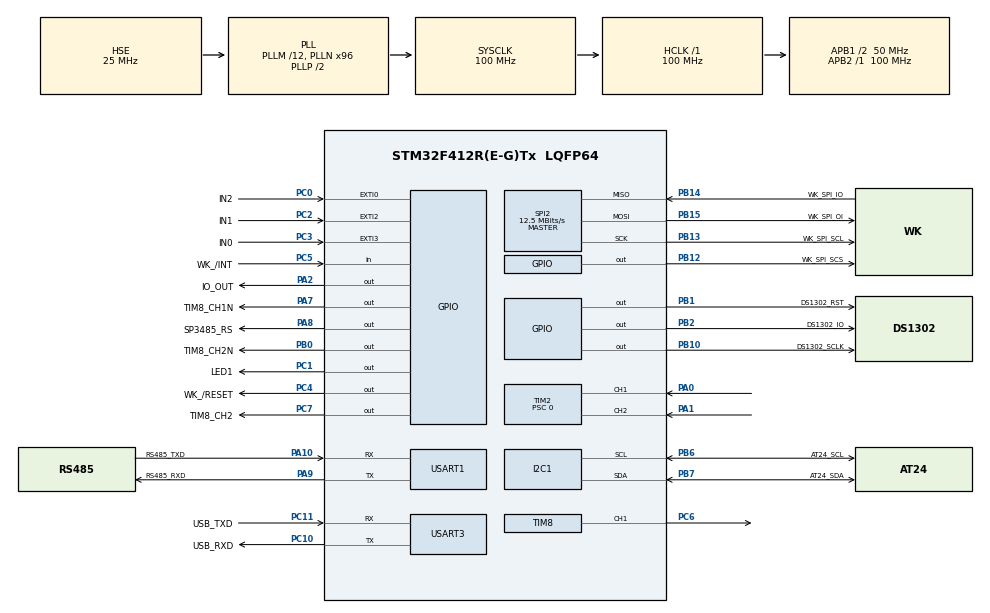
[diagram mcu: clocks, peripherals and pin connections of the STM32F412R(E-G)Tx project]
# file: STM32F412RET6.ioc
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Dma.Request0=USART1_RX
Dma.Request1=USART1_TX
Dma.USART1_RX.0.Direction=DMA_PERIPH_TO_MEMORY
Dma.USART1_RX.0.FIFOMode=DMA_FIFOMODE_DISABLE
Dma.USART1_RX.0.Instance=DMA2_Stream2
Dma.USART1_RX.0.MemDataAlignment=DMA_MDATAALIGN_BYTE
Dma.USART1_RX.0.MemInc=DMA_MINC_ENABLE
Dma.USART1_RX.0.Mode=DMA_NORMAL
Dma.USART1_RX.0.PeriphDataAlignment=DMA_PDATAALIGN_BYTE
Dma.USART1_RX.0.PeriphInc=DMA_PINC_DISABLE
Dma.USART1_RX.0.Priority=DMA_PRIORITY_LOW
Dma.USART1_TX.1.Direction=DMA_MEMORY_TO_PERIPH
Dma.USART1_TX.1.FIFOMode=DMA_FIFOMODE_DISABLE
Dma.USART1_TX.1.Instance=DMA2_Stream7
Dma.USART1_TX.1.MemDataAlignment=DMA_MDATAALIGN_BYTE
Dma.USART1_TX.1.MemInc=DMA_MINC_ENABLE
Dma.USART1_TX.1.Mode=DMA_NORMAL
Dma.USART1_TX.1.PeriphDataAlignment=DMA_PDATAALIGN_BYTE
Dma.USART1_TX.1.PeriphInc=DMA_PINC_DISABLE
Dma.USART1_TX.1.Priority=DMA_PRIORITY_LOW
FREERTOS.Queues01=myQueue01,5,uint8_t,0,Dynamic,NULL,NULL
FREERTOS.Tasks01=defaultTask,24,128,StartDefaultTask,Default,NULL,Dynamic,NULL,NULL;myTask01,8,128,StartTask01,Default,NULL,Dynamic,NULL,NULL
FREERTOS.configMAX_TASK_NAME_LEN=32
I2C1.I2C_Mode=I2C_Fast
Mcu.Family=STM32F4
Mcu.Name=STM32F412R(E-G)Tx
Mcu.Package=LQFP64
NVIC.DMA2_Stream2_IRQn=true\:5\:0\:false\:false\:true\:true\:false\:true\:true
NVIC.DMA2_Stream7_IRQn=true\:5\:0\:false\:false\:true\:true\:false\:true\:true
NVIC.EXTI0_IRQn=true\:5\:0\:false\:false\:true\:true\:true\:true\:true
NVIC.EXTI2_IRQn=true\:5\:0\:false\:false\:true\:true\:true\:true\:true
NVIC.EXTI3_IRQn=true\:5\:0\:false\:false\:true\:true\:true\:true\:true
NVIC.I2C1_ER_IRQn=true\:5\:0\:false\:false\:true\:true\:true\:true\:true
NVIC.I2C1_EV_IRQn=true\:5\:0\:false\:false\:true\:true\:true\:true\:true
NVIC.PriorityGroup=NVIC_PRIORITYGROUP_4
NVIC.SPI2_IRQn=true\:5\:0\:false\:false\:true\:true\:true\:true\:true
NVIC.TIM1_UP_TIM10_IRQn=true\:15\:0\:false\:false\:true\:false\:false\:true\:true
NVIC.TIM2_IRQn=true\:5\:0\:true\:false\:true\:true\:true\:true\:true
NVIC.TIM3_IRQn=true\:6\:0\:true\:false\:true\:true\:true\:true\:true
NVIC.TIM8_BRK_TIM12_IRQn=true\:5\:0\:false\:false\:true\:true\:true\:true\:true
NVIC.TIM8_CC_IRQn=true\:5\:0\:false\:false\:true\:true\:true\:true\:true
NVIC.TIM8_TRG_COM_TIM14_IRQn=true\:5\:0\:false\:false\:true\:true\:true\:true\:true
NVIC.TIM8_UP_TIM13_IRQn=true\:5\:0\:false\:false\:true\:true\:true\:true\:true
NVIC.TimeBase=TIM1_UP_TIM10_IRQn
NVIC.TimeBaseIP=TIM1
NVIC.USART1_IRQn=true\:5\:0\:false\:false\:true\:true\:true\:true\:true
NVIC.USART3_IRQn=true\:5\:0\:false\:false\:true\:true\:true\:true\:true
PA0.GPIO_PuPd=GPIO_PULLUP
PA0.Signal=S_TIM2_CH1_ETR
PA1.GPIO_PuPd=GPIO_PULLUP
PA1.Signal=S_TIM2_CH2
PA10.GPIO_Label=RS485_TXD
PA10.Mode=Asynchronous
PA10.Signal=USART1_RX
PA13.GPIO_Label=TMS
PA13.Mode=JTAG_5_pins
PA13.Signal=SYS_JTMS-SWDIO
PA14.GPIO_Label=TCK
PA14.Mode=JTAG_5_pins
PA14.Signal=SYS_JTCK-SWCLK
PA15.GPIO_Label=TDI
PA15.Mode=JTAG_5_pins
PA15.Signal=SYS_JTDI
PA2.GPIO_Label=IO_OUT
PA2.GPIO_PuPd=GPIO_PULLDOWN
PA2.Signal=GPIO_Output
PA7.GPIO_Label=TIM8_CH1N
PA7.GPIO_PuPd=GPIO_PULLDOWN
PA7.Signal=GPIO_Output
PA8.GPIO_Label=SP3485_RS
PA8.Signal=GPIO_Output
PA9.GPIO_Label=RS485_RXD
PA9.Mode=Asynchronous
PA9.Signal=USART1_TX
PB0.GPIO_Label=TIM8_CH2N
PB0.GPIO_PuPd=GPIO_PULLUP
PB0.Signal=GPIO_Output
PB1.GPIO_Label=DS1302_RST
PB1.Signal=GPIO_Output
PB10.GPIO_Label=DS1302_SCLK
PB10.GPIO_PuPd=GPIO_PULLUP
PB10.Signal=GPIO_Output
PB12.GPIO_Label=WK_SPI_SCS
PB12.GPIO_ModeDefaultOutputPP=GPIO_MODE_OUTPUT_PP
PB12.GPIO_PuPd=GPIO_PULLUP
PB12.Signal=GPIO_Output
PB13.GPIO_Label=WK_SPI_SCL
PB13.Mode=Full_Duplex_Master
PB13.Signal=SPI2_SCK
PB14.GPIO_Label=WK_SPI_IO
PB14.Mode=Full_Duplex_Master
PB14.Signal=SPI2_MISO
PB15.GPIO_Label=WK_SPI_OI
PB15.Mode=Full_Duplex_Master
PB15.Signal=SPI2_MOSI
PB2.GPIO_Label=DS1302_IO
PB2.Signal=GPIO_Output
PB3.GPIO_Label=TDO
PB3.Mode=JTAG_5_pins
PB3.Signal=SYS_JTDO-SWO
PB4.GPIO_Label=NTRST
PB4.Mode=JTAG_5_pins
PB4.Signal=SYS_JTRST
PB6.GPIO_Label=AT24_SCL
PB6.Mode=I2C
PB6.Signal=I2C1_SCL
PB7.GPIO_Label=AT24_SDA
PB7.Mode=I2C
PB7.Signal=I2C1_SDA
PC0.GPIO_Label=IN2
PC0.GPIO_ModeDefaultEXTI=GPIO_MODE_IT_FALLING
PC0.Signal=GPXTI0
PC1.GPIO_Label=LED1
PC1.GPIO_PuPd=GPIO_PULLUP
PC1.Signal=GPIO_Output
PC10.GPIO_Label=USB_RXD
PC10.Mode=Asynchronous
PC10.Signal=USART3_TX
PC11.GPIO_Label=USB_TXD
PC11.Mode=Asynchronous
PC11.Signal=USART3_RX
PC2.GPIO_Label=IN1
PC2.GPIO_ModeDefaultEXTI=GPIO_MODE_IT_FALLING
PC2.Signal=GPXTI2
PC3.GPIO_Label=IN0
PC3.GPIO_ModeDefaultEXTI=GPIO_MODE_IT_FALLING
PC3.Signal=GPXTI3
PC4.GPIO_Label=WK_/RESET
PC4.Signal=GPIO_Output
PC5.GPIO_Label=WK_/INT
PC5.Signal=GPIO_Input
PC6.GPIO_Speed=GPIO_SPEED_FREQ_HIGH
PC6.Signal=S_TIM8_CH1
PC7.GPIO_Label=TIM8_CH2
PC7.GPIO_PuPd=GPIO_PULLUP
PC7.Signal=GPIO_Output
PH0\ -\ OSC_IN.Mode=HSE-External-Oscillator
PH0\ -\ OSC_IN.Signal=RCC_OSC_IN
PH1\ -\ OSC_OUT.Mode=HSE-External-Oscillator
PH1\ -\ OSC_OUT.Signal=RCC_OSC_OUT
ProjectManager.HeapSize=0x200
ProjectManager.StackSize=0x400
ProjectManager.TargetToolchain=MDK-ARM V5.32
RCC.AHBFreq_Value=100000000
RCC.APB1CLKDivider=RCC_HCLK_DIV2
RCC.APB1Freq_Value=50000000
RCC.APB1TimFreq_Value=100000000
RCC.APB2Freq_Value=100000000
RCC.APB2TimFreq_Value=100000000
RCC.CortexFreq_Value=100000000
RCC.HCLKFreq_Value=100000000
RCC.PLLM=12
RCC.PLLN=96
RCC.PLLSourceVirtual=RCC_PLLSOURCE_HSE
RCC.SYSCLKFreq_VALUE=100000000
RCC.SYSCLKSource=RCC_SYSCLKSOURCE_PLLCLK
RCC.USBFreq_Value=100000000
RCC.VCOOutputFreq_Value=200000000
SH.S_TIM2_CH1_ETR.0=TIM2_CH1,Encoder_Interface
SH.S_TIM2_CH2.0=TIM2_CH2,Encoder_Interface
SH.S_TIM8_CH1.0=TIM8_CH1,PWM Generation1 CH1
SPI2.BaudRatePrescaler=SPI_BAUDRATEPRESCALER_4
SPI2.CLKPhase=SPI_PHASE_2EDGE
SPI2.CLKPolarity=SPI_POLARITY_HIGH
SPI2.CalculateBaudRate=12.5 MBits/s
SPI2.Direction=SPI_DIRECTION_2LINES
SPI2.Mode=SPI_MODE_MASTER
SPI2.VirtualType=VM_MASTER
TIM13.Period=500-1
TIM13.Prescaler=10-1
TIM2.EncoderMode=TIM_ENCODERMODE_TI12
TIM2.IC1Filter=6
TIM2.IC2Filter=6
TIM2.Period=20000
TIM2.Prescaler=0
TIM3.AutoReloadPreload=TIM_AUTORELOAD_PRELOAD_ENABLE
TIM3.Period=5000-1
TIM3.Prescaler=100-1
TIM8.AutoReloadPreload=TIM_AUTORELOAD_PRELOAD_DISABLE
TIM8.Channel-PWM\ Generation1\ CH1=TIM_CHANNEL_1
TIM8.Period=50-1
TIM8.Prescaler=100-1
TIM8.Pulse-PWM\ Generation1\ CH1=5
USART1.VirtualMode=VM_ASYNC
USART3.VirtualMode=VM_ASYNC
VP_FREERTOS_VS_CMSIS_V2.Mode=CMSIS_V2
VP_SYS_VS_tim1.Mode=TIM1
VP_TIM13_VS_ClockSourceINT.Mode=Enable_Timer
VP_TIM3_VS_ClockSourceINT.Mode=Internal
board=custom

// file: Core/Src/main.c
/* USER CODE BEGIN Header */
/**
  ******************************************************************************
  * @file           : main.c
  * @brief          : Main program body
  ******************************************************************************
  * @attention
  *
  * Copyright (c) 2024 STMicroelectronics.
  * All rights reserved.
  *
  * This software is licensed under terms that can be found in the LICENSE file
  * in the root directory of this software component.
  * If no LICENSE file comes with this software, it is provided AS-IS.
  *
  ******************************************************************************
  */
/* USER CODE END Header */
#include "main.h"
#include "cmsis_os.h"
#include "dma.h"
#include "i2c.h"
#include "spi.h"
#include "tim.h"
#include "usart.h"
#include "gpio.h"

/* USER CODE BEGIN PTD */
float speed_Record[SPEED_RECORD_NUM]={0};

/* USER CODE END PTD */

/* USER CODE BEGIN PD */
float Speed_Low_Filter(float new_Spe,float *speed_Record);
/* USER CODE END PD */

void SystemClock_Config(void);
void MX_FREERTOS_Init(void);

int main(void)
{

  /* MCU Configuration--------------------------------------------------------*/

  /* Reset of all peripherals, Initializes the Flash interface and the Systick. */
  HAL_Init();

  /* Configure the system clock */
  SystemClock_Config();

  /* Initialize all configured peripherals */
  MX_GPIO_Init();
  MX_DMA_Init();
  MX_TIM2_Init();
  MX_USART1_UART_Init();
  MX_I2C1_Init();
  MX_SPI2_Init();
  MX_TIM3_Init();
  MX_TIM8_Init();
  MX_TIM13_Init();
  MX_USART3_UART_Init();

  /* Init scheduler */
  osKernelInitialize();  /* Call init function for freertos objects (in freertos.c) */
  MX_FREERTOS_Init();

  /* Start scheduler */
  osKernelStart();

  /* We should never get here as control is now taken by the scheduler */
  /* Infinite loop */
  while (1)
  {

  }
}

void SystemClock_Config(void)
{
  RCC_OscInitTypeDef RCC_OscInitStruct = {0};
  RCC_ClkInitTypeDef RCC_ClkInitStruct = {0};

  /** Configure the main internal regulator output voltage
  */
  __HAL_RCC_PWR_CLK_ENABLE();
  __HAL_PWR_VOLTAGESCALING_CONFIG(PWR_REGULATOR_VOLTAGE_SCALE1);

  /** Initializes the RCC Oscillators according to the specified parameters
  * in the RCC_OscInitTypeDef structure.
  */
  RCC_OscInitStruct.OscillatorType = RCC_OSCILLATORTYPE_HSE;
  RCC_OscInitStruct.HSEState = RCC_HSE_ON;
  RCC_OscInitStruct.PLL.PLLState = RCC_PLL_ON;
  RCC_OscInitStruct.PLL.PLLSource = RCC_PLLSOURCE_HSE;
  RCC_OscInitStruct.PLL.PLLM = 12;
  RCC_OscInitStruct.PLL.PLLN = 96;
  RCC_OscInitStruct.PLL.PLLP = RCC_PLLP_DIV2;
  RCC_OscInitStruct.PLL.PLLQ = 2;
  RCC_OscInitStruct.PLL.PLLR = 2;
  if (HAL_RCC_OscConfig(&RCC_OscInitStruct) != HAL_OK)
  {
    Error_Handler();
  }

  /** Initializes the CPU, AHB and APB buses clocks
  */
  RCC_ClkInitStruct.ClockType = RCC_CLOCKTYPE_HCLK|RCC_CLOCKTYPE_SYSCLK
                              |RCC_CLOCKTYPE_PCLK1|RCC_CLOCKTYPE_PCLK2;
  RCC_ClkInitStruct.SYSCLKSource = RCC_SYSCLKSOURCE_PLLCLK;
  RCC_ClkInitStruct.AHBCLKDivider = RCC_SYSCLK_DIV1;
  RCC_ClkInitStruct.APB1CLKDivider = RCC_HCLK_DIV2;
  RCC_ClkInitStruct.APB2CLKDivider = RCC_HCLK_DIV1;

  if (HAL_RCC_ClockConfig(&RCC_ClkInitStruct, FLASH_LATENCY_3) != HAL_OK)
  {
    Error_Handler();
  }
}

/* USER CODE BEGIN 4 */

void HAL_GPIO_EXTI_Callback(uint16_t GPIO_Pin)//GPIO中断回调函数
{
	if(GPIO_Pin==IN0_Pin)
	{
		__HAL_GPIO_EXTI_CLEAR_IT(IN0_Pin);//清除中断标志位
		if(Extreme_position_flag==0&&Sports_status_flag==1)
		{
			HAL_TIM_PWM_Stop_IT(&htim8,TIM_CHANNEL_1);//关闭PWM输出
			Extreme_position_flag=1;
		}
	}

	else if(GPIO_Pin==IN1_Pin)//原点
	{
		if(Position_flag==0)
		{
			Position_flag=1;
			HAL_TIM_PWM_Stop_IT(&htim8,TIM_CHANNEL_1);//关闭PWM输出
			HAL_GPIO_WritePin(TIM8_CH1N_GPIO_Port,TIM8_CH1N_Pin,GPIO_PIN_SET);//PA7-电机使能正输入(GPIO_PIN_RESET:开始，GPIO_PIN_SET:停止）
			Sports_status_flag=0;
			Zero_regression_flag=1;
			Hard_Trigger_Current_Number=0;
		}
//		else if(Position_flag==1)//自检
//		{
//			Position_flag=2;
//		}
		Encoder_Processing_flag=1;
		__HAL_TIM_SetCounter(&htim2, 10000);//校验位置
		__HAL_GPIO_EXTI_CLEAR_IT(IN1_Pin);//清除中断标志位
	}

	else if(GPIO_Pin==IN2_Pin)
	{
		__HAL_GPIO_EXTI_CLEAR_IT(IN2_Pin);//清除中断标志位
		if(Extreme_position_flag==0&&Sports_status_flag==1)
		{
			HAL_TIM_PWM_Stop_IT(&htim8,TIM_CHANNEL_1);//关闭PWM输出
			Extreme_position_flag=1;
		}
	}
}

/*
 * 进行速度的平均滤波
 * 输入新采样到的速度，存放速度的数组，
 * 返回滤波后的速度
 */
float Speed_Low_Filter(float new_Spe,float *speed_Record)
{
    float sum = 0.0f;
    float test_Speed;
    for(uint8_t i=SPEED_RECORD_NUM-1;i>0;i--)//将现有数据后移一位
    {
        speed_Record[i] = speed_Record[i-1];
        sum += speed_Record[i-1];
    }
    speed_Record[0] = new_Spe;//第一位是新的数据
    sum += new_Spe;
    test_Speed = sum/SPEED_RECORD_NUM;
    return test_Speed;//返回均值
}

//void Motor_Rive(GPIO_PinState enable,GPIO_PinState direction,uint16_t number)//电机驱动函数
//{
//	uint8_t number_i=0xff;
//	if(number>0x05)
//	{
//		HAL_GPIO_WritePin(TIM8_CH1N_GPIO_Port,TIM8_CH1N_Pin,enable);//PA7-电机使能正输入(GPIO_PIN_RESET:开始，GPIO_PIN_SET:停止）
//		osDelay(1);
//		HAL_GPIO_WritePin(TIM8_CH2_GPIO_Port,TIM8_CH2_Pin,direction);//PC7-电机方向控制(GPIO_PIN_RESET:顺时针，GPIO_PIN_SET:逆时针）
//		osDelay(1);
//		HAL_TIM_Base_Start_IT(&htim8);//开启TIM8定时器中断（20KHZ，周期50us）
//		while(number_i>number)
//		{
//			number_i--;
//			__HAL_TIM_SET_AUTORELOAD(&htim8,number_i);//修改自动重装载值
//	//		__HAL_TIM_PRESCALER(&htim8,number);//修改预分频值
//	//		TIM8->CCR1 = running_speed_value;//修改占空比
//	//		__HAL_TIM_SET_COMPARE(&htim8, TIM_CHANNEL_1, number);//修改占空比
//			HAL_TIM_PWM_Start_IT(&htim8,TIM_CHANNEL_1);//启动TIM8_CH1的PWM波输出（中断）
//			if(number_i>=0x96)
//			{
//				HAL_Delay(2);
//			}
//			else if(0x96>number_i&&number_i>=0x28)
//			{
//				HAL_Delay(15);
//			}
//			else
//			{
//				HAL_Delay(20);
//			}
//		}
//		number_i=0xff;
//	}
//}

/* USER CODE END 4 */

void HAL_TIM_PeriodElapsedCallback(TIM_HandleTypeDef *htim)
{
  if (htim->Instance == TIM1) {
    HAL_IncTick();
  }
  /* USER CODE BEGIN Callback 1 */
	else if(htim->Instance==TIM3)//间隔定时器中断，是时候计算速度了（10us处理一次）
	{
		Encoder_Processing_flag=1;
	}

	else if(htim->Instance==TIM2)//编码器溢出更新中断
	{
		if(COUNTERNUM < 10000)	motor1.overflowNum++;         //向上计数超过10000，正溢出+1
		else if(COUNTERNUM > 10000)	motor1.overflowNum--;     //向下计数小于0，负溢出+1
		__HAL_TIM_SetCounter(&htim2, 10000);             //重新设定初始值
	}

//	else if(htim->Instance==TIM8)//PWM输出
//	{
//
//	}
	else if(htim->Instance==TIM13)//硬触发定时50us一次
	{
		HAL_GPIO_WritePin(IO_OUT_GPIO_Port, IO_OUT_Pin, GPIO_PIN_RESET);//硬触发关闭
		HAL_TIM_Base_Stop_IT(&htim13);
		Hard_Trigger_flag=1;
	}
  /* USER CODE END Callback 1 */
}

void Error_Handler(void)
{
  __disable_irq();
  while (1)
  {
  }
}

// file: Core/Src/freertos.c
/* USER CODE BEGIN Header */
/**
  ******************************************************************************
  * File Name          : freertos.c
  * Description        : Code for freertos applications
  ******************************************************************************
  * @attention
  *
  * Copyright (c) 2024 STMicroelectronics.
  * All rights reserved.
  *
  * This software is licensed under terms that can be found in the LICENSE file
  * in the root directory of this software component.
  * If no LICENSE file comes with this software, it is provided AS-IS.
  *
  ******************************************************************************
  */
/* USER CODE END Header */

#include "FreeRTOS.h"
#include "task.h"
#include "main.h"
#include "cmsis_os.h"

/* USER CODE BEGIN PTD */
wiz_NetInfo gWIZNETINFO = {
  .mac = { 0x80, 0x80, 0x80,0x80,0x80,0x80 },//MSB - LSB
  .ip  = { 192, 168, 1, 11 },
  .sn  = { 255, 255, 255, 0 },
  .gw  = { 192, 168, 1, 1 },//网关参数
  .dns  = { 8, 8, 8, 8 },
  .dhcp = NETINFO_STATIC };

uint8_t receive_buff[RECEIVE_BUFF_SIZE];

Motor motor1;
float Position=0;//距0点位置,单位mm
uint32_t Position_upload=0;//距0点距离上传值（单位0.001mm）
uint32_t zero_return_speed_value=2000;//回零速度（单位0.001mm/s）
uint16_t pwmVal_TIM8 = 0;  //占空比大小(CCRx的大小，高电平时间)
uint8_t Position_flag=0;//原点位置标志位
uint8_t Sports_status_flag=0;//运动状态标志位
uint8_t Extreme_position_flag=0;//极限位置标志位
uint8_t Position_upload_flag=1;//位置上传标志位
uint8_t Encoder_Processing_flag=0;//编码器数据处理标志位
uint8_t Zero_regression_flag=0;//是否回零过标志位
uint8_t Absolute_position_flag=0;//绝对位置标志位
float Track_Length=0;//轨道长，单位毫米
uint32_t Target_Position=0;//目标位置
uint32_t Zero_Position=0;//零点位置
uint8_t Sports_mode=0;//运动模式
uint16_t Hard_Trigger_Number=0;//硬触发个数
uint16_t Hard_Trigger_Current_Number=0;//硬触发当前个数
uint32_t Hard_Trigger_Interval=0;//硬触发时间间隔
uint32_t Hard_Trigger_Position=0;//硬触发开始位置
uint8_t Hard_Trigger_start_flag=0;//硬触发开始标志位
uint8_t Hard_Trigger_flag=0;//硬触发标志位
/* USER CODE END PTD */

/* Definitions for defaultTask */
osThreadId_t defaultTaskHandle;
const osThreadAttr_t defaultTask_attributes = {
  .name = "defaultTask",
  .stack_size = 128 * 4,
  .priority = (osPriority_t) osPriorityNormal,
};
/* Definitions for myTask01 */
osThreadId_t myTask01Handle;
const osThreadAttr_t myTask01_attributes = {
  .name = "myTask01",
  .stack_size = 128 * 4,
  .priority = (osPriority_t) osPriorityLow,
};
/* Definitions for myQueue01 */
osMessageQueueId_t myQueue01Handle;
const osMessageQueueAttr_t myQueue01_attributes = {
  .name = "myQueue01"
};

/* USER CODE BEGIN FunctionPrototypes */
osThreadId_t Ethernet_ServerTaskHandle;
const osThreadAttr_t Ethernet_ServerTask_attributes = {
  .name = "Ethernet_ServerTask",
  .stack_size = 256 * 4,
  .priority = (osPriority_t) osPriorityLow,
};

osThreadId_t EncoderTaskHandle;
const osThreadAttr_t EncoderTask_attributes = {
  .name = "EncoderTask",
  .stack_size = 128 * 4,
  .priority = (osPriority_t) osPriorityLow,
};

osThreadId_t DriveTaskHandle;
const osThreadAttr_t DriveTask_attributes = {
  .name = "DriveTask",
  .stack_size = 128 * 4,
  .priority = (osPriority_t) osPriorityLow,
};

osThreadId_t Motor_driveTaskHandle;
const osThreadAttr_t Motor_driveTask_attributes = {
  .name = "Motor_driveTask",
  .stack_size = 128 * 4,
  .priority = (osPriority_t) osPriorityLow,
};

osThreadId_t Pulse_EmissionTaskHandle;
const osThreadAttr_t Pulse_EmissionTask_attributes = {
  .name = "Pulse_EmissionTask",
  .stack_size = 128 * 4,
  .priority = (osPriority_t) osPriorityLow,
};

osThreadId_t Extreme_position_DriveTaskHandle;
const osThreadAttr_t Extreme_position_DriveTask_attributes = {
  .name = "Extreme_position_DriveTask",
  .stack_size = 128 * 4,
  .priority = (osPriority_t) osPriorityLow,
};

osMessageQueueId_t Ethernet_ReceiveHandle;
const osMessageQueueAttr_t Ethernet_Receive_attributes = {
  .name = "Ethernet_Receive"
};

osMessageQueueId_t Ethernet_SendHandle;
const osMessageQueueAttr_t Ethernet_Send_attributes = {
  .name = "Ethernet_Send"
};

osMessageQueueId_t Motor_driveQueueHandle;
const osMessageQueueAttr_t Motor_driveQueue_attributes = {
  .name = "Motor_driveQueue"
};

void Ethernet_Server(void *argument);//网络通信-服务端
void Encoder(void *argument);//电动机编码器通讯
void Drive(void *argument);//控制驱动器
void Motor_drive(void *argument);//电动驱动
void Pulse_Emission(void *argument);//脉冲发射
void Extreme_position_Drive(void *argument);//极限位置控制
/* USER CODE END FunctionPrototypes */

void StartDefaultTask(void *argument);
void StartTask01(void *argument);
void MX_FREERTOS_Init(void); /* (MISRA C 2004 rule 8.1) */

void MX_FREERTOS_Init(void) {

  /* Create the queue(s) */
  /* creation of myQueue01 */
  myQueue01Handle = osMessageQueueNew (5, sizeof(uint8_t), &myQueue01_attributes);

  /* Create the thread(s) */
  /* creation of defaultTask */
  defaultTaskHandle = osThreadNew(StartDefaultTask, NULL, &defaultTask_attributes);

  /* creation of myTask01 */
  myTask01Handle = osThreadNew(StartTask01, NULL, &myTask01_attributes);

  /* USER CODE BEGIN RTOS_THREADS */
	Ethernet_ServerTaskHandle = osThreadNew(Ethernet_Server, NULL, &Ethernet_ServerTask_attributes);
	EncoderTaskHandle = osThreadNew(Encoder, NULL, &EncoderTask_attributes);
	DriveTaskHandle = osThreadNew(Drive, NULL, &DriveTask_attributes);
	Motor_driveTaskHandle = osThreadNew(Motor_drive, NULL, &Motor_driveTask_attributes);
	Pulse_EmissionTaskHandle = osThreadNew(Pulse_Emission, NULL, &Pulse_EmissionTask_attributes);
	Extreme_position_DriveTaskHandle = osThreadNew(Extreme_position_Drive, NULL, &Extreme_position_DriveTask_attributes);

	Ethernet_ReceiveHandle = osMessageQueueNew (5, 20*sizeof(uint8_t), &Ethernet_Receive_attributes);
	Ethernet_SendHandle = osMessageQueueNew (5, 20*sizeof(uint8_t), &Ethernet_Send_attributes);
	Motor_driveQueueHandle = osMessageQueueNew (5, 3*sizeof(uint8_t), &Motor_driveQueue_attributes);

  /* add threads, ... */
  /* USER CODE END RTOS_THREADS */

  /* USER CODE BEGIN RTOS_EVENTS */
	if(HAL_GPIO_ReadPin(IN1_GPIO_Port,IN1_Pin)==GPIO_PIN_RESET)//在原点
	{
		Position=0;
		Position_flag=1;
		Zero_regression_flag=1;
	}
	else
	{
		Position=1499;
	}
  /* add events, ... */
  /* USER CODE END RTOS_EVENTS */

}

void StartDefaultTask(void *argument)
{
  for(;;)
  {
    osDelay(1);
  }
}

void StartTask01(void *argument)
{
  /* USER CODE BEGIN StartTask01 */
  /* Infinite loop */
  for(;;)
  {
    osDelay(1);
		osDelay(100);
		HAL_GPIO_TogglePin(GPIOC, LED1_Pin);
  }
  /* USER CODE END StartTask01 */
}

/* USER CODE BEGIN Application */

void Ethernet_Server(void *argument)//网口通信-服务端
{
  W5500Init();//w5500初始化
  ctlnetwork(CN_SET_NETINFO, (void*)&gWIZNETINFO);  //配置网络参数
  wiz_PhyConf phyconf;
  phyconf.by = PHY_CONFBY_SW;
  phyconf.duplex = PHY_DUPLEX_FULL;
  phyconf.speed = PHY_SPEED_10;
  phyconf.mode = PHY_MODE_AUTONEGO;
  ctlwizchip(CW_SET_PHYCONF, (void*)&phyconf); //配置PHY参数
  for(;;)
  {
		net_process_socket(1, LISTEN_PORT_1);
		net_process_socket(2, LISTEN_PORT_2);
		osDelay(20);
  }
}

void Drive(void *argument)//控制驱动器
{
	uint8_t	send_buff[13];
	uint8_t status=0;
	uint32_t running_speed_value=1500;//运行速度
	uint32_t zero_return_creep_speed_value=0;//回零蠕变速度
	uint8_t Drive_control_array[20];	//驱动器控制数组
	uint16_t Data_Bytes=0;//数据字节
	uint8_t Motor_drive_send[3];//电机驱动数组
  for(;;)
  {
		osDelay(1);
		status=osMessageQueueGet(Ethernet_ReceiveHandle,Drive_control_array,NULL,10);
		if(status==osOK)
		{
			send_buff[0]=Drive_control_array[0];//0X19;事务处理标识
			send_buff[1]=Drive_control_array[1];//0XB2;事务处理标识
			send_buff[2]=0X00;//协议标识符，00 00为modbus协议
			send_buff[3]=0X00;//协议标识符，00 00为modbus协议
			send_buff[6]=Drive_control_array[6];//0XDB;设备地址
			send_buff[7]=Drive_control_array[7];//功能码
			switch(Drive_control_array[7])//判断功能码
			{
				case 0x01://读线圈(MBAP 功能码 起始地址H 起始地址L 线圈数量H 线圈数量L)
					if(Drive_control_array[8]==0x20)//判断起始地址
					{
						switch(Drive_control_array[9])//判断起始地址
						{
							case 0x0A://原点回归完成标志

								break;

							case 0x64://伺服运动状态
								send_buff[4]=0X00;//数据长度
								send_buff[5]=0X05;//数据长度
								send_buff[8]=0X01;//接下来数据的字节长度
								if(Sports_status_flag==1)//运动
								{
									send_buff[9]=0X01;//数据
								}
								else if(Sports_status_flag==0)//停止
								{
									send_buff[9]=0X00;//数据
								}
								send(1,send_buff,10);//向客户端发送
								memset(send_buff,0,13);
								break;

							case 0x01://原点回归/停止
								send_buff[4]=0X00;//数据长度
								send_buff[5]=0X05;//数据长度
								send_buff[8]=0X01;//接下来数据的字节长度
								if(Sports_status_flag==1)//在原点
								{
									send_buff[9]=0X01;
								}
								else if(Sports_status_flag==0)//不在原点
								{
									send_buff[9]=0X00;
								}
								send(1,send_buff,10);//向客户端发送
								memset(send_buff,0,13);
								break;

							case 0x02://正转点动/停止

								break;

							case 0x03://反转点动/停止

								break;

							case 0x04://相对运动/停止

								break;

							case 0x05://绝对运动/停止
								send_buff[4]=0X00;//数据长度
								send_buff[5]=0X05;//数据长度
								send_buff[8]=0X01;//接下来数据的字节长度
								if(Sports_status_flag==1)//运动
								{
									send_buff[9]=0X01;//数据
								}
								else if(Sports_status_flag==0)//停止
								{
									send_buff[9]=0X00;//数据
								}
								send(1,send_buff,10);//向客户端发送
								memset(send_buff,0,13);
								break;

							case 0x00://硬触发启动/停止
								send_buff[4]=0X00;//数据长度
								send_buff[5]=0X05;//数据长度
								send_buff[8]=0X01;//接下来数据的字节长度
								if(Hard_Trigger_start_flag==1)//触发
								{
									send_buff[9]=0X01;//数据
								}
								else//停止
								{
									send_buff[9]=0X00;//数据
								}
								send(1,send_buff,10);//向客户端发送
								memset(send_buff,0,13);
								break;

							case 0x06://伺服复位
								send_buff[4]=0X00;//数据长度
								send_buff[5]=0X05;//数据长度
								send_buff[8]=0X01;//接下来数据的字节长度
								if(Position_flag==1)//在原点
								{
									send_buff[9]=0X01;
								}
								else if(Position_flag==0)//不在原点
								{
									send_buff[9]=0X00;
								}
								send(1,send_buff,10);//向客户端发送
								memset(send_buff,0,13);
								break;

							case 0x09://雷达上电/断电
								send_buff[4]=0X00;//数据长度
								send_buff[5]=0X06;//数据长度
								send_buff[8]=0X01;//接下来数据的字节长度
//								if()//上电
//								{
//									send_buff[9]=0X01;//数据
//								}
//								else//
//								{
//									send_buff[9]=0X00;//数据
//								}
								send(1,send_buff,10);//向客户端发送
								memset(send_buff,0,13);
								break;

							default:
								break;
						}
					}
					break;

				case 0x02://读离散量输入
					send_buff[4]=0X00;//数据长度
					send_buff[5]=0X04;//数据长度
					send_buff[8]=0X01;//接下来数据的字节长度
					if(Drive_control_array[8]==0x00&&Drive_control_array[9]==0x01)//判断起始地址——正转极限光电状态
					{
						if(HAL_GPIO_ReadPin(IN2_GPIO_Port,IN2_Pin)==GPIO_PIN_RESET)//到达限位
						{
							send_buff[9]=0X01;//数据
							send(1,send_buff,10);//向客户端发送
							memset(send_buff,0,13);
						}
						else
						{
							send_buff[9]=0X00;//数据
							send(1,send_buff,10);//向客户端发送
							memset(send_buff,0,13);
						}
					}
					else if(Drive_control_array[8]==0x00&&Drive_control_array[9]==0x03)//判断起始地址——反转极限光电状态
					{
						if(HAL_GPIO_ReadPin(IN0_GPIO_Port,IN0_Pin)==GPIO_PIN_RESET)//到达限位
						{
							send_buff[9]=0X01;//数据
							send(1,send_buff,10);//向客户端发送
							memset(send_buff,0,13);
						}
						else
						{
							send_buff[9]=0X00;//数据
							send(1,send_buff,10);//向客户端发送
							memset(send_buff,0,13);
						}
					}
					else if(Drive_control_array[8]==0x00&&Drive_control_array[9]==0x04)//判断起始地址——零点限位触发状态
					{
						if(HAL_GPIO_ReadPin(IN1_GPIO_Port,IN1_Pin)==GPIO_PIN_RESET)//到达限位
						{
							send_buff[9]=0X01;//数据
							send(1,send_buff,10);//向客户端发送
							memset(send_buff,0,13);
						}
						else
						{
							send_buff[9]=0X00;//数据
							send(1,send_buff,10);//向客户端发送
							memset(send_buff,0,13);
						}
					}
					else if(Drive_control_array[8]==0x00&&Drive_control_array[9]==0x05)//判断起始地址——伺服报警状态
					{

					}
					break;

				case 0x03://读保持寄存器(MBAP 功能码 起始地址H 起始地址L 寄存器数量H 寄存器数量L)
					Data_Bytes=(Drive_control_array[10]<<8|Drive_control_array[11])*2;//大端传输数据处理——读取数据字节
					send_buff[4]=0X00;//数据长度
					send_buff[5]=0x03+Data_Bytes;//数据长度
					if(Drive_control_array[8]==0x01)//判断起始地址
					{
						if(Data_Bytes==0x02)
						{
							if(Drive_control_array[9]==0x4A)//判断起始地址——加速时间
							{
								send_buff[8]=Data_Bytes;//接下来数据的字节长度
								send_buff[9]=0X00;//数据
								send_buff[10]=0X00;//数据
								send(1,send_buff,11);//向客户端发送
								memset(send_buff,0,13);
							}
							else if(Drive_control_array[9]==0x4E)//判断起始地址——减速时间
							{
								send_buff[8]=Data_Bytes;//接下来数据的字节长度
								send_buff[9]=0X00;//数据
								send_buff[10]=0X00;//数据
								send(1,send_buff,11);//向客户端发送
								memset(send_buff,0,13);
							}
							else if(Drive_control_array[9]==0x00)//判断起始地址——实时位置上传控制
							{
								send_buff[8]=Data_Bytes;//接下来数据的字节长度
								send_buff[9]=(Position_upload>>8)&0xFF;//数据
								send_buff[10]=Position_upload&0xFF;//数据
								send(1,send_buff,11);//向客户端发送
								memset(send_buff,0,13);
							}
							else if(Drive_control_array[9]==0x30)//判断起始地址——硬触发个数
							{
								send_buff[8]=Data_Bytes;//接下来数据的字节长度
								send_buff[9]=(Hard_Trigger_Number>>8)&0xFF;//数据
								send_buff[10]=Hard_Trigger_Number&0xFF;//数据
								send(1,send_buff,11);//向客户端发送
								memset(send_buff,0,13);
							}
							else if(Drive_control_array[9]==0x32)//判断起始地址——当前硬触发个数
							{
								send_buff[8]=Data_Bytes;//接下来数据的字节长度
								send_buff[9]=0X00;//数据
								send_buff[10]=0X00;//数据
								send(1,send_buff,11);//向客户端发送
								memset(send_buff,0,13);
							}
							else if(Drive_control_array[9]==0x77)//判断起始地址——上电后是否执行过归零
							{
								send_buff[8]=Data_Bytes;//接下来数据的字节长度
								if(Zero_regression_flag==1)
								{
									send_buff[9]=0X00;//数据
									send_buff[10]=0X01;//数据
									send(1,send_buff,11);//向客户端发送
									memset(send_buff,0,13);
								}
								else if(Zero_regression_flag==0)
								{
									send_buff[9]=0X00;//数据
									send_buff[10]=0X00;//数据
									send(1,send_buff,11);//向客户端发送
									memset(send_buff,0,13);
								}
							}
						}
						else if(Data_Bytes==0x04)
						{
							if(Drive_control_array[9]==0x2C)//判断起始地址——起始硬触发位置
							{
								send_buff[8]=Data_Bytes;//接下来数据的字节长度
								send_buff[11]=(Hard_Trigger_Position>>24)&0xFF;//数据
								send_buff[12]=(Hard_Trigger_Position>>16)&0xFF;//数据
								send_buff[9]=(Hard_Trigger_Position>>8)&0xFF;//数据
								send_buff[10]=Hard_Trigger_Position&0xFF;//数据
								send(1,send_buff,13);//向客户端发送
								memset(send_buff,0,13);
							}
							else if(Drive_control_array[9]==0x2E)//判断起始地址——硬触发间隔
							{
								send_buff[8]=Data_Bytes;//接下来数据的字节长度
								send_buff[11]=(Hard_Trigger_Interval>>24)&0xFF;//寄存器1H-数据
								send_buff[12]=(Hard_Trigger_Interval>>16)&0xFF;//寄存器1L数据
								send_buff[9]=(Hard_Trigger_Interval>>8)&0xFF;//寄存器2H数据
								send_buff[10]=Hard_Trigger_Interval&0xFF;//寄存器2L数据
								send(1,send_buff,13);//向客户端发送
								memset(send_buff,0,13);
							}
						}
					}

					else if(Drive_control_array[8]==0x00)//判断起始地址
					{
						if(Data_Bytes==0x02)
						{
							if(Drive_control_array[9]==0x20)//判断起始地址——伺服错误代码
							{
								send_buff[8]=Data_Bytes;//接下来数据的字节长度
								send_buff[9]=0X00;//数据
								send_buff[10]=0X00;//数据
								send(1,send_buff,11);//向客户端发送
								memset(send_buff,0,13);
							}
							else if(Drive_control_array[9]==0x96)//判断起始地址——PLC错误代码
							{
								send_buff[8]=Data_Bytes;//接下来数据的字节长度
								send_buff[9]=0X00;//数据
								send_buff[10]=0X00;//数据
								send(1,send_buff,11);//向客户端发送
								memset(send_buff,0,13);
							}
						}
						else if(Data_Bytes==0x04)
						{
							if(Drive_control_array[9]==0x64)//判断起始地址——回零速度
							{
								send_buff[8]=Data_Bytes;//接下来数据的字节长度
								send_buff[11]=(zero_return_speed_value>>24)&0xFF;//数据
								send_buff[12]=(zero_return_speed_value>>16)&0xFF;//数据
								send_buff[9]=(zero_return_speed_value>>8)&0xFF;//数据
								send_buff[10]=zero_return_speed_value&0xFF;//数据
								send(1,send_buff,13);//向客户端发送
								memset(send_buff,0,13);
							}
							else if(Drive_control_array[9]==0x68)//判断起始地址——回零蠕变速度
							{
								send_buff[8]=Data_Bytes;//接下来数据的字节长度
								send_buff[11]=(zero_return_creep_speed_value>>24)&0xFF;//寄存器1H-数据
								send_buff[12]=(zero_return_creep_speed_value>>16)&0xFF;//寄存器1L-数据
								send_buff[9]=(zero_return_creep_speed_value>>8)&0xFF;//寄存器2H-数据
								send_buff[10]=zero_return_creep_speed_value&0xFF;//寄存器2L-数据
								send(1,send_buff,13);//向客户端发送
								memset(send_buff,0,13);
							}
							else if(Drive_control_array[9]==0x78)//判断起始地址——运行速度
							{
								send_buff[8]=Data_Bytes;//接下来数据的字节长度
								send_buff[11]=(running_speed_value>>24)&0xFF;//寄存器1H-数据
								send_buff[12]=(running_speed_value>>16)&0xFF;//寄存器1L-数据
								send_buff[9]=(running_speed_value>>8)&0xFF;//寄存器2H-数据
								send_buff[10]=running_speed_value&0xFF;//寄存器2L-数据
								send(1,send_buff,13);//向客户端发送
								memset(send_buff,0,13);
							}
							else if(Drive_control_array[9]==0x7A)//判断起始地址——相对定位距离
							{
								send_buff[8]=Data_Bytes;//接下来数据的字节长度
								send_buff[11]=0X00;//寄存器1H-数据
								send_buff[12]=0X00;//寄存器1L-数据
								send_buff[9]=0X00;//寄存器2H-数据
								send_buff[10]=0X00;//寄存器2L-数据
								send(1,send_buff,13);//向客户端发送
								memset(send_buff,0,13);
							}
							else if(Drive_control_array[9]==0x7C)//判断起始地址——绝对定位位置
							{
								send_buff[8]=Data_Bytes;//接下来数据的字节长度
								send_buff[11]=(Target_Position>>24)&0xFF;//寄存器1H-数据
								send_buff[12]=(Target_Position>>16)&0xFF;//寄存器1L-数据
								send_buff[9]=(Target_Position>>8)&0xFF;//寄存器2H-数据
								send_buff[10]=Target_Position&0xFF;//寄存器2L-数据
								send(1,send_buff,13);//向客户端发送
								memset(send_buff,0,13);
							}
							else if(Drive_control_array[9]==0x7E)//判断起始地址——设备最大运行行程
							{
								send_buff[8]=Data_Bytes;//接下来数据的字节长度
								send_buff[9]=0X00;//寄存器1H-数据
								send_buff[10]=0X00;//寄存器1L-数据
								send_buff[11]=0X00;//寄存器2H-数据
								send_buff[12]=0X00;//寄存器2L-数据
								send(1,send_buff,13);//向客户端发送
								memset(send_buff,0,13);
							}
							else if(Drive_control_array[9]==0x80)//判断起始地址——零点位置坐标
							{
								send_buff[8]=Data_Bytes;//接下来数据的字节长度
								send_buff[11]=(Zero_Position>>24)&0xFF;//寄存器1H-数据
								send_buff[12]=(Zero_Position>>16)&0xFF;//寄存器1L-数据
								send_buff[9]=(Zero_Position>>8)&0xFF;//寄存器2H-数据
								send_buff[10]=Zero_Position&0xFF;//寄存器2L-数据
								send(1,send_buff,13);//向客户端发送
								memset(send_buff,0,13);
							}
							else if(Drive_control_array[9]==0x87)//判断起始地址——实时位置主动读取
							{
								send_buff[8]=Data_Bytes;//接下来数据的字节长度
								send_buff[11]=(Position_upload>>24)&0xFF;//寄存器1H-数据
								send_buff[12]=(Position_upload>>16)&0xFF;//寄存器1L-数据
								send_buff[9]=(Position_upload>>8)&0xFF;//寄存器2H-数据
								send_buff[10]=Position_upload&0xFF;//寄存器2L-数据
								send(1,send_buff,13);//向客户端发送
								memset(send_buff,0,13);
							}
						}
					}
					break;

				case 0x05://写单个线圈(请求：MBAP 功能码 寄存器地址H 寄存器地址L 数据H(FF/00) 数据L(00))
					send_buff[4]=0X00;//数据长度
					send_buff[5]=0X06;//数据长度
					send_buff[8]=Drive_control_array[8];//寄存器地址H
					send_buff[9]=Drive_control_array[9];//寄存器地址H
					if(Drive_control_array[8]==0x20)//判断起始地址
					{
						switch(Drive_control_array[9])//判断起始地址
						{
							case 0x01://原点回归/停止
								if(Drive_control_array[10]==0xFF)//回归
								{
									if(Position_flag==0)//不在原点
									{
										if(Sports_status_flag==0)//判断运动状态
										{
											send_buff[10]=0XFF;
											send_buff[11]=0X00;
											send(1,send_buff,12);//向客户端发送
											memset(send_buff,0,13);
											Sports_status_flag=1;
											if(zero_return_speed_value==500)
											{
												Motor_drive_send[0]=GPIO_PIN_SET;//方向
												Motor_drive_send[1]=0x00;//速度H
												Motor_drive_send[2]=0x4C;//速度L
												osMessageQueuePut(Motor_driveQueueHandle,Motor_drive_send,1,0);
	//											Motor_Rive(GPIO_PIN_RESET,GPIO_PIN_SET,0x4C);//开始，顺时针，原点回归速度
											}
											else if(zero_return_speed_value==1000)
											{
												Motor_drive_send[0]=GPIO_PIN_SET;
												Motor_drive_send[1]=0x00;
												Motor_drive_send[2]=0x26;
												osMessageQueuePut(Motor_driveQueueHandle,Motor_drive_send,1,0);
	//											Motor_Rive(GPIO_PIN_RESET,GPIO_PIN_SET,0x26);//开始，顺时针，原点回归速度
											}
											else if(zero_return_speed_value==1500)
											{
												Motor_drive_send[0]=GPIO_PIN_SET;
												Motor_drive_send[1]=0x00;
												Motor_drive_send[2]=0x19;
												osMessageQueuePut(Motor_driveQueueHandle,Motor_drive_send,1,0);
	//											Motor_Rive(GPIO_PIN_RESET,GPIO_PIN_SET,0x19);//开始，顺时针，原点回归速度
											}
											else if(zero_return_speed_value==2000)
											{
												Motor_drive_send[0]=GPIO_PIN_SET;
												Motor_drive_send[1]=0x00;
												Motor_drive_send[2]=0x12;
												osMessageQueuePut(Motor_driveQueueHandle,Motor_drive_send,1,0);
	//											Motor_Rive(GPIO_PIN_RESET,GPIO_PIN_SET,0x12);//开始，顺时针，原点回归速度
											}
											else if(zero_return_speed_value>=2500)
											{
												Motor_drive_send[0]=GPIO_PIN_SET;
												Motor_drive_send[1]=0x00;
												Motor_drive_send[2]=0x0F;
												osMessageQueuePut(Motor_driveQueueHandle,Motor_drive_send,1,0);
	//											Motor_Rive(GPIO_PIN_RESET,GPIO_PIN_SET,0x0F);//开始，顺时针，原点回归速度
											}
										}
									}
								}
								else if(Drive_control_array[10]==0x00)//停止
								{
									send_buff[10]=0X00;
									send_buff[11]=0X00;
									send(1,send_buff,12);//向客户端发送
									memset(send_buff,0,13);
									HAL_TIM_PWM_Stop_IT(&htim8,TIM_CHANNEL_1);//关闭PWM输出
									HAL_GPIO_WritePin(TIM8_CH1N_GPIO_Port,TIM8_CH1N_Pin,GPIO_PIN_SET);//PA7-电机使能正输入(GPIO_PIN_RESET:开始，GPIO_PIN_SET:停止）
									Sports_status_flag=0;
								}
								break;

							case 0x02://正转点动/停止
								if(Drive_control_array[10]==0xFF)//开始
								{
									send_buff[10]=0XFF;
									send_buff[11]=0X00;
									send(1,send_buff,12);//向客户端发送
									memset(send_buff,0,13);
									Sports_status_flag=1;
									Position_flag=0;
									if(running_speed_value==500)
									{
										Motor_drive_send[0]=GPIO_PIN_RESET;
										Motor_drive_send[1]=0x00;
										Motor_drive_send[2]=0x4C;
										osMessageQueuePut(Motor_driveQueueHandle,Motor_drive_send,1,0);
//										Motor_Rive(GPIO_PIN_RESET,GPIO_PIN_RESET,0x4C);//开始，顺时针，原点回归速度
									}
									else if(running_speed_value==1000)
									{
										Motor_drive_send[0]=GPIO_PIN_RESET;
										Motor_drive_send[1]=0x00;
										Motor_drive_send[2]=0x26;
										osMessageQueuePut(Motor_driveQueueHandle,Motor_drive_send,1,0);
//										Motor_Rive(GPIO_PIN_RESET,GPIO_PIN_RESET,0x26);//开始，顺时针，原点回归速度
									}
									else if(running_speed_value==1500)
									{
										Motor_drive_send[0]=GPIO_PIN_RESET;
										Motor_drive_send[1]=0x00;
										Motor_drive_send[2]=0x19;
										osMessageQueuePut(Motor_driveQueueHandle,Motor_drive_send,1,0);
//										Motor_Rive(GPIO_PIN_RESET,GPIO_PIN_RESET,0x19);//开始，顺时针，原点回归速度
									}
									else if(running_speed_value==2000)
									{
										Motor_drive_send[0]=GPIO_PIN_RESET;
										Motor_drive_send[1]=0x00;
										Motor_drive_send[2]=0x12;
										osMessageQueuePut(Motor_driveQueueHandle,Motor_drive_send,1,0);
//										Motor_Rive(GPIO_PIN_RESET,GPIO_PIN_RESET,0x12);//开始，顺时针，原点回归速度
									}
									else if(running_speed_value>=2500)
									{
										Motor_drive_send[0]=GPIO_PIN_RESET;
										Motor_drive_send[1]=0x00;
										Motor_drive_send[2]=0x0F;
										osMessageQueuePut(Motor_driveQueueHandle,Motor_drive_send,1,0);
//										Motor_Rive(GPIO_PIN_RESET,GPIO_PIN_RESET,0x0F);//开始，顺时针，原点回归速度
									}
								}
								else//停止
								{
									send_buff[10]=0X00;
									send_buff[11]=0X00;
									send(1,send_buff,12);//向客户端发送
									memset(send_buff,0,13);
									HAL_TIM_PWM_Stop_IT(&htim8,TIM_CHANNEL_1);//关闭PWM输出
									HAL_GPIO_WritePin(TIM8_CH1N_GPIO_Port,TIM8_CH1N_Pin,GPIO_PIN_SET);//PA7-电机使能正输入(GPIO_PIN_RESET:开始，GPIO_PIN_SET:停止）
									Sports_status_flag=0;
								}
								break;

							case 0x03://反转点动/停止
								if(Drive_control_array[10]==0xFF)//开始
								{
									send_buff[10]=0XFF;
									send_buff[11]=0X00;
									send(1,send_buff,12);//向客户端发送
									memset(send_buff,0,13);
									Sports_status_flag=1;
									Position_flag=0;
									if(running_speed_value==500)
									{
										Motor_drive_send[0]=GPIO_PIN_SET;
										Motor_drive_send[1]=0x00;
										Motor_drive_send[2]=0x4C;
										osMessageQueuePut(Motor_driveQueueHandle,Motor_drive_send,1,0);
//										Motor_Rive(GPIO_PIN_RESET,GPIO_PIN_SET,0x4C);//开始，顺时针，原点回归速度
									}
									else if(running_speed_value==1000)
									{
										Motor_drive_send[0]=GPIO_PIN_SET;
										Motor_drive_send[1]=0x00;
										Motor_drive_send[2]=0x26;
										osMessageQueuePut(Motor_driveQueueHandle,Motor_drive_send,1,0);
//										Motor_Rive(GPIO_PIN_RESET,GPIO_PIN_SET,0x26);//开始，顺时针，原点回归速度
									}
									else if(running_speed_value==1500)
									{
										Motor_drive_send[0]=GPIO_PIN_SET;
										Motor_drive_send[1]=0x00;
										Motor_drive_send[2]=0x19;
										osMessageQueuePut(Motor_driveQueueHandle,Motor_drive_send,1,0);
//										Motor_Rive(GPIO_PIN_RESET,GPIO_PIN_SET,0x19);//开始，顺时针，原点回归速度
									}
									else if(running_speed_value==2000)
									{
										Motor_drive_send[0]=GPIO_PIN_SET;
										Motor_drive_send[1]=0x00;
										Motor_drive_send[2]=0x12;
										osMessageQueuePut(Motor_driveQueueHandle,Motor_drive_send,1,0);
//										Motor_Rive(GPIO_PIN_RESET,GPIO_PIN_SET,0x12);//开始，顺时针，原点回归速度
									}
									else if(running_speed_value>=2500)
									{
										Motor_drive_send[0]=GPIO_PIN_SET;
										Motor_drive_send[1]=0x00;
										Motor_drive_send[2]=0x0F;
										osMessageQueuePut(Motor_driveQueueHandle,Motor_drive_send,1,0);
//										Motor_Rive(GPIO_PIN_RESET,GPIO_PIN_SET,0x0F);//开始，顺时针，原点回归速度
									}
								}
								else//停止
								{
									send_buff[10]=0X00;
									send_buff[11]=0X00;
									send(1,send_buff,12);//向客户端发送
									memset(send_buff,0,13);
									HAL_TIM_PWM_Stop_IT(&htim8,TIM_CHANNEL_1);//关闭PWM输出
									HAL_GPIO_WritePin(TIM8_CH1N_GPIO_Port,TIM8_CH1N_Pin,GPIO_PIN_SET);//PA7-电机使能正输入(GPIO_PIN_RESET:开始，GPIO_PIN_SET:停止）
									Sports_status_flag=0;
								}
								break;

							case 0x04://相对运动/停止
								if(Drive_control_array[10]==0xFF)//开始
								{
									send_buff[10]=0XFF;
									send_buff[11]=0X00;
									send(1,send_buff,12);//向客户端发送
									memset(send_buff,0,13);
									if(Sports_status_flag==0)
									{
										Position_flag=0;
										Sports_status_flag=1;
										if(running_speed_value==500)
										{
											Motor_drive_send[0]=GPIO_PIN_RESET;
											Motor_drive_send[1]=0x00;
											Motor_drive_send[2]=0x4C;
											osMessageQueuePut(Motor_driveQueueHandle,Motor_drive_send,1,0);
//											Motor_Rive(GPIO_PIN_RESET,GPIO_PIN_RESET,0x4C);//开始，顺时针，原点回归速度
										}
										else if(running_speed_value==1000)
										{
											Motor_drive_send[0]=GPIO_PIN_RESET;
											Motor_drive_send[1]=0x00;
											Motor_drive_send[2]=0x26;
											osMessageQueuePut(Motor_driveQueueHandle,Motor_drive_send,1,0);
//											Motor_Rive(GPIO_PIN_RESET,GPIO_PIN_RESET,0x26);//开始，顺时针，原点回归速度
										}
										else if(running_speed_value==1500)
										{
											Motor_drive_send[0]=GPIO_PIN_RESET;
											Motor_drive_send[1]=0x00;
											Motor_drive_send[2]=0x19;
											osMessageQueuePut(Motor_driveQueueHandle,Motor_drive_send,1,0);
//											Motor_Rive(GPIO_PIN_RESET,GPIO_PIN_RESET,0x19);//开始，顺时针，原点回归速度
										}
										else if(running_speed_value==2000)
										{
											Motor_drive_send[0]=GPIO_PIN_RESET;
											Motor_drive_send[1]=0x00;
											Motor_drive_send[2]=0x12;
											osMessageQueuePut(Motor_driveQueueHandle,Motor_drive_send,1,0);
//											Motor_Rive(GPIO_PIN_RESET,GPIO_PIN_RESET,0x12);//开始，顺时针，原点回归速度
										}
										else if(running_speed_value>=2500)
										{
											Motor_drive_send[0]=GPIO_PIN_RESET;
											Motor_drive_send[1]=0x00;
											Motor_drive_send[2]=0x0F;
											osMessageQueuePut(Motor_driveQueueHandle,Motor_drive_send,1,0);
//											Motor_Rive(GPIO_PIN_RESET,GPIO_PIN_RESET,0x0F);//开始，顺时针，原点回归速度
										}
									}
								}
								else//停止
								{
									send_buff[10]=0X00;
									send_buff[11]=0X00;
									send(1,send_buff,12);//向客户端发送
									memset(send_buff,0,13);
									HAL_TIM_PWM_Stop_IT(&htim8,TIM_CHANNEL_1);//关闭PWM输出
									HAL_GPIO_WritePin(TIM8_CH1N_GPIO_Port,TIM8_CH1N_Pin,GPIO_PIN_SET);//PA7-电机使能正输入(GPIO_PIN_RESET:开始，GPIO_PIN_SET:停止）
									Sports_status_flag=0;
								}
								break;

							case 0x05://绝对运动/停止
								if(Drive_control_array[10]==0xFF)//开始
								{
									send_buff[10]=0XFF;
									send_buff[11]=0X00;
									send(1,send_buff,12);//向客户端发送
									memset(send_buff,0,13);
									if(Sports_status_flag==0)
									{
										Position_flag=0;
										Sports_status_flag=1;
//										Continuous_control_Time=xTaskGetTickCount();
										if(Position_upload*10<Target_Position)//当前位置小于目标位置-正向移动
										{
											if(running_speed_value==500)
											{
												Motor_drive_send[0]=GPIO_PIN_RESET;
												Motor_drive_send[1]=0x00;
												Motor_drive_send[2]=0x4C;
												osMessageQueuePut(Motor_driveQueueHandle,Motor_drive_send,1,0);
	//											Motor_Rive(GPIO_PIN_RESET,GPIO_PIN_RESET,0x4C);//开始，顺时针，原点回归速度
											}
											else if(running_speed_value==1000)
											{
												Motor_drive_send[0]=GPIO_PIN_RESET;
												Motor_drive_send[1]=0x00;
												Motor_drive_send[2]=0x26;
												osMessageQueuePut(Motor_driveQueueHandle,Motor_drive_send,1,0);
	//											Motor_Rive(GPIO_PIN_RESET,GPIO_PIN_RESET,0x26);//开始，顺时针，原点回归速度
											}
											else if(running_speed_value==1500)
											{
												Motor_drive_send[0]=GPIO_PIN_RESET;
												Motor_drive_send[1]=0x00;
												Motor_drive_send[2]=0x19;
												osMessageQueuePut(Motor_driveQueueHandle,Motor_drive_send,1,0);
	//											Motor_Rive(GPIO_PIN_RESET,GPIO_PIN_RESET,0x19);//开始，顺时针，原点回归速度
											}
											else if(running_speed_value==2000)
											{
												Motor_drive_send[0]=GPIO_PIN_RESET;
												Motor_drive_send[1]=0x00;
												Motor_drive_send[2]=0x12;
												osMessageQueuePut(Motor_driveQueueHandle,Motor_drive_send,1,0);
	//											Motor_Rive(GPIO_PIN_RESET,GPIO_PIN_RESET,0x12);//开始，顺时针，原点回归速度
											}
											else if(running_speed_value>=2500)
											{
												Motor_drive_send[0]=GPIO_PIN_RESET;
												Motor_drive_send[1]=0x00;
												Motor_drive_send[2]=0x0F;
												osMessageQueuePut(Motor_driveQueueHandle,Motor_drive_send,1,0);
	//											Motor_Rive(GPIO_PIN_RESET,GPIO_PIN_RESET,0x0F);//开始，顺时针，原点回归速度
											}
										}
										else if(Position_upload*10>Target_Position)//当前位置大于目标位置-反向移动
										{
											if(running_speed_value==500)
											{
												Motor_drive_send[0]=GPIO_PIN_SET;
												Motor_drive_send[1]=0x00;
												Motor_drive_send[2]=0x4C;
												osMessageQueuePut(Motor_driveQueueHandle,Motor_drive_send,1,0);
	//											Motor_Rive(GPIO_PIN_RESET,GPIO_PIN_RESET,0x4C);//开始，顺时针，原点回归速度
											}
											else if(running_speed_value==1000)
											{
												Motor_drive_send[0]=GPIO_PIN_SET;
												Motor_drive_send[1]=0x00;
												Motor_drive_send[2]=0x26;
												osMessageQueuePut(Motor_driveQueueHandle,Motor_drive_send,1,0);
	//											Motor_Rive(GPIO_PIN_RESET,GPIO_PIN_RESET,0x26);//开始，顺时针，原点回归速度
											}
											else if(running_speed_value==1500)
											{
												Motor_drive_send[0]=GPIO_PIN_SET;
												Motor_drive_send[1]=0x00;
												Motor_drive_send[2]=0x19;
												osMessageQueuePut(Motor_driveQueueHandle,Motor_drive_send,1,0);
	//											Motor_Rive(GPIO_PIN_RESET,GPIO_PIN_RESET,0x19);//开始，顺时针，原点回归速度
											}
											else if(running_speed_value==2000)
											{
												Motor_drive_send[0]=GPIO_PIN_SET;
												Motor_drive_send[1]=0x00;
												Motor_drive_send[2]=0x12;
												osMessageQueuePut(Motor_driveQueueHandle,Motor_drive_send,1,0);
	//											Motor_Rive(GPIO_PIN_RESET,GPIO_PIN_RESET,0x12);//开始，顺时针，原点回归速度
											}
											else if(running_speed_value>=2500)
											{
												Motor_drive_send[0]=GPIO_PIN_SET;
												Motor_drive_send[1]=0x00;
												Motor_drive_send[2]=0x0F;
												osMessageQueuePut(Motor_driveQueueHandle,Motor_drive_send,1,0);
	//											Motor_Rive(GPIO_PIN_RESET,GPIO_PIN_RESET,0x0F);//开始，顺时针，原点回归速度
											}
										}
									}
								}
								else//停止
								{
									send_buff[10]=0X00;
									send_buff[11]=0X00;
									send(1,send_buff,12);//向客户端发送
									memset(send_buff,0,13);
									HAL_TIM_PWM_Stop_IT(&htim8,TIM_CHANNEL_1);//关闭PWM输出
									HAL_GPIO_WritePin(TIM8_CH1N_GPIO_Port,TIM8_CH1N_Pin,GPIO_PIN_SET);//PA7-电机使能正输入(GPIO_PIN_RESET:开始，GPIO_PIN_SET:停止）
									Sports_status_flag=0;
								}
								break;

							case 0x14://停止运动状态
								if(Drive_control_array[10]==0xFF)//停止
								{
									HAL_TIM_PWM_Stop_IT(&htim8,TIM_CHANNEL_1);//关闭PWM输出
									HAL_GPIO_WritePin(TIM8_CH1N_GPIO_Port,TIM8_CH1N_Pin,GPIO_PIN_SET);//PA7-电机使能正输入(GPIO_PIN_RESET:开始，GPIO_PIN_SET:停止）
									Sports_status_flag=0;
									send_buff[10]=0XFF;
									send_buff[11]=0X00;
								}
								else
								{
									send_buff[10]=0X00;
									send_buff[11]=0X00;
								}
								send(1,send_buff,12);//向客户端发送
								memset(send_buff,0,13);
								break;

							case 0x00://硬触发启动/停止
								if(Drive_control_array[10]==0xFF)//开始
								{
									Hard_Trigger_start_flag=1;
									send_buff[10]=0XFF;
									send_buff[11]=0X00;
								}
								else//停止
								{
									Hard_Trigger_start_flag=0;
									send_buff[10]=0X00;
									send_buff[11]=0X00;
								}
								send(1,send_buff,12);//向客户端发送
								memset(send_buff,0,13);
								break;

							case 0x06://伺服复位
								if(Drive_control_array[10]==0xFF)
								{
									send_buff[10]=0XFF;
									send_buff[11]=0X00;
									send(1,send_buff,12);//向客户端发送
									memset(send_buff,0,13);
								}
								else if(Drive_control_array[10]==0x00)
								{
									send_buff[10]=0X00;
									send_buff[11]=0X00;
									send(1,send_buff,12);//向客户端发送
									memset(send_buff,0,13);
								}
								break;

							case 0x07://伺服急停
								if(Drive_control_array[10]==0xFF)
								{
									send_buff[10]=0XFF;
									send_buff[11]=0X00;
								}
								else
								{
									send_buff[10]=0X00;
									send_buff[11]=0X00;
								}
								send(1,send_buff,12);//向客户端发送
								memset(send_buff,0,13);
								break;

							case 0x09://雷达上电/断电
								if(Drive_control_array[10]==0xFF)
								{
									send_buff[10]=0XFF;
									send_buff[11]=0X00;
								}
								else
								{
									send_buff[10]=0X00;
									send_buff[11]=0X00;
								}
								send(1,send_buff,12);//向客户端发送
								memset(send_buff,0,13);
								break;

							case 0x0F://PLC错误清除
								if(Drive_control_array[10]==0xFF)
								{
									send_buff[10]=0XFF;
									send_buff[11]=0X00;
								}
								else
								{
									send_buff[10]=0X00;
									send_buff[11]=0X00;
								}
								send(1,send_buff,12);//向客户端发送
								memset(send_buff,0,13);
								break;

							default:
								break;
						}
					}
					break;

				case 0x06://写单个保持寄存器(请求：MBAP 功能码 寄存器地址H 寄存器地址L 寄存器值H 寄存器值L)
//					if(Sports_status_flag==0)//未开始运动
//					{
						send_buff[4]=0X00;//数据长度
						send_buff[5]=0X06;//数据长度
						send_buff[8]=Drive_control_array[8];//寄存器地址
						send_buff[9]=Drive_control_array[9];//寄存器地址
						send_buff[10]=Drive_control_array[10];//寄存器值H
						send_buff[11]=Drive_control_array[11];//寄存器值L
						if(Drive_control_array[8]==0x01)//判断起始地址
						{
							if(Drive_control_array[9]==0x4A)//判断起始地址——加速时间
							{
								send(1,send_buff,12);//向客户端发送
								memset(send_buff,0,13);
							}
							else if(Drive_control_array[9]==0x4E)//判断起始地址——减速时间
							{
								send(1,send_buff,12);//向客户端发送
								memset(send_buff,0,13);
							}
							else if(Drive_control_array[9]==0x00)//判断起始地址——实时位置上传控制
							{
								if(Drive_control_array[10]||Drive_control_array[11])
								{
									Position_upload_flag=1;//开始实时位置上传
								}
								else
								{
									Position_upload_flag=0;//停止实时位置上传
								}
								send(1,send_buff,12);//向客户端发送
								memset(send_buff,0,13);
							}
							else if(Drive_control_array[9]==0x30)//判断起始地址——硬触发个数
							{
								Hard_Trigger_Number=(Drive_control_array[10]<<8|Drive_control_array[11]);//大端传输数据处理——硬触发个数
								send(1,send_buff,12);//向客户端发送
								memset(send_buff,0,13);
							}
						}
//					}
					break;

				case 0x10://写多个保持寄存器(请求：MBAP(7位) 功能码 起始地址H 起始地址L 寄存器数量H 寄存器数量L 字节长度 寄存器值)
//					if(Sports_status_flag==0)//未开始运动
//					{
						send_buff[4]=0X00;//数据长度
						send_buff[5]=0X06;//数据长度
						send_buff[8]=Drive_control_array[8];//寄存器起始地址H
						send_buff[9]=Drive_control_array[9];//寄存器起始地址L
						send_buff[10]=Drive_control_array[10];//寄存器数量H
						send_buff[11]=Drive_control_array[11];//寄存器数量L
						if(Drive_control_array[8]==0x00)//判断起始地址
						{
							if(Drive_control_array[9]==0x64)//判断起始地址——回零速度
							{
								zero_return_speed_value=(Drive_control_array[13]<<8|Drive_control_array[14]|Drive_control_array[15]<<24|Drive_control_array[16]<<16);//大端传输数据处理——回零速度0.001mm/s
								send(1,send_buff,12);//向客户端发送
								memset(send_buff,0,13);
							}
							else if(Drive_control_array[9]==0x68)//判断起始地址——回零蠕变速度
							{
								zero_return_creep_speed_value=(Drive_control_array[13]<<8|Drive_control_array[14]|Drive_control_array[15]<<24|Drive_control_array[16]<<16);//大端传输数据处理——回零蠕变速度0.001mm/s
								send(1,send_buff,12);//向客户端发送
								memset(send_buff,0,13);
							}
							else if(Drive_control_array[9]==0x78)//判断起始地址——运行速度
							{
								running_speed_value=(Drive_control_array[13]<<8|Drive_control_array[14]|Drive_control_array[15]<<24|Drive_control_array[16]<<16);//大端传输数据处理——运行速度0.001mm/s
								send(1,send_buff,12);//向客户端发送
								memset(send_buff,0,13);
							}
							else if(Drive_control_array[9]==0x7A)//判断起始地址——相对定位距离
							{
								send(1,send_buff,12);//向客户端发送
								memset(send_buff,0,13);
							}
							else if(Drive_control_array[9]==0x7C)//判断起始地址——绝对定位位置
							{
								Absolute_position_flag=1;
								Target_Position=(Drive_control_array[13]<<8|Drive_control_array[14]|Drive_control_array[15]<<24|Drive_control_array[16]<<16);//大端传输数据处理——绝对定位位置0.001mm
								send(1,send_buff,12);//向客户端发送
								memset(send_buff,0,13);
							}
							else if(Drive_control_array[9]==0x7E)//判断起始地址——设备最大运行行程
							{
								send(1,send_buff,12);//向客户端发送
								memset(send_buff,0,13);
							}
							else if(Drive_control_array[9]==0x80)//判断起始地址——零点位置坐标
							{
								Zero_Position=(Drive_control_array[13]<<8|Drive_control_array[14]|Drive_control_array[15]<<24|Drive_control_array[16]<<16);//大端传输数据处理——零点位置0.001mm
								send(1,send_buff,12);//向客户端发送
								memset(send_buff,0,13);
							}
						}
						else if(Drive_control_array[8]==0x01)//判断起始地址
						{
							if(Drive_control_array[9]==0x2C)//判断起始地址——起始硬触发位置
							{
								Hard_Trigger_Position=(Drive_control_array[13]<<8|Drive_control_array[14]|Drive_control_array[15]<<24|Drive_control_array[16]<<16);//大端传输数据处理——起始硬触发位置0.001mm
								send(1,send_buff,12);//向客户端发送
								memset(send_buff,0,13);
							}
							else if(Drive_control_array[9]==0x2E)//判断起始地址——硬触发间隔
							{
								Hard_Trigger_Interval=(Drive_control_array[13]<<8|Drive_control_array[14]|Drive_control_array[15]<<24|Drive_control_array[16]<<16);//大端传输数据处理——硬触发间隔0.001mm
								send(1,send_buff,12);//向客户端发送
								memset(send_buff,0,13);
							}
						}
//					}
					break;

				default:
					break;
			}
			memset(Drive_control_array,0,20);
		}
  }
}

void Motor_drive(void *argument)//电动驱动
{
	uint8_t status=0;
	uint8_t number_i=0xff;
	uint16_t number;
	uint8_t Motor_drive_receive[3];//电机驱动数组
	for(;;)
	{
//		osDelay(1);
		status=osMessageQueueGet(Motor_driveQueueHandle,Motor_drive_receive,NULL,10);
		if(status==osOK)
		{
			if(Sports_status_flag==1)
			{
				number=Motor_drive_receive[1]<<8|Motor_drive_receive[2];
				if(number>0x05)
				{
					HAL_GPIO_WritePin(TIM8_CH1N_GPIO_Port,TIM8_CH1N_Pin,GPIO_PIN_RESET);//PA7-电机使能正输入(GPIO_PIN_RESET:开始，GPIO_PIN_SET:停止）
					osDelay(1);
					HAL_GPIO_WritePin(TIM8_CH2_GPIO_Port,TIM8_CH2_Pin,(GPIO_PinState)Motor_drive_receive[0]);//PC7-电机方向控制(GPIO_PIN_RESET:顺时针，GPIO_PIN_SET:逆时针）
					osDelay(1);
					HAL_TIM_Base_Start_IT(&htim8);//开启TIM8定时器中断（20KHZ，周期50us）
					while(number_i>number)
					{
						number_i--;
						__HAL_TIM_SET_AUTORELOAD(&htim8,number_i);//修改自动重装载值
				//		__HAL_TIM_PRESCALER(&htim8,number);//修改预分频值
				//		TIM8->CCR1 = running_speed_value;//修改占空比
				//		__HAL_TIM_SET_COMPARE(&htim8, TIM_CHANNEL_1, number);//修改占空比
						HAL_TIM_PWM_Start_IT(&htim8,TIM_CHANNEL_1);//启动TIM8_CH1的PWM波输出（中断）
						if(number_i>=0x96)
						{
							osDelay(2);
						}
						else if(0x96>number_i&&number_i>=0x28)
						{
							osDelay(15);
						}
						else
						{
							osDelay(20);
						}
					}
					number_i=0xff;
				}
			}
		}
		memset(Motor_drive_receive,0,3);
	}
}

float sd;
uint32_t Trigger_Interval;//触发间隔
void Encoder(void *argument)//电动机编码器通讯
{
	uint8_t Real_time_location_array[6]={0xCF,0xAE,0x00,0x00,0x00,0x00};//实时位置数组
	HAL_TIM_Encoder_Start(&htim2, TIM_CHANNEL_ALL);      //开启编码器定时器
	__HAL_TIM_ENABLE_IT(&htim2,TIM_IT_UPDATE);          //开启编码器定时器更新中断,防溢出处理
	HAL_TIM_Base_Start_IT(&htim3);                    //开启100ms定时器中断
	__HAL_TIM_SetCounter(&htim2, 10000);               //编码器定时器初始值设定为10000
	motor1.lastCount = 0;                               //结构体内容初始化
	motor1.totalCount = 0;
	motor1.overflowNum = 0;
	motor1.speed = 0;
	motor1.direct = 0;
	motor1.distance = 0;
	Position_upload=0;
  for(;;)
  {
//		osDelay(1);
		if(Encoder_Processing_flag==1)
		{
			Encoder_Processing_flag=0;
			motor1.direct = __HAL_TIM_IS_TIM_COUNTING_DOWN(&htim2);//如果向上计数（正转），返回值为0，否则返回值为1
			int16_t pluse = COUNTERNUM - (RELOADVALUE)/2;
			motor1.totalCount = pluse+ motor1.overflowNum * (int16_t)RELOADVALUE/2;//从开始到现在当前5ms的总脉冲数
			motor1.speed = (float)(motor1.totalCount - motor1.lastCount) / (4 * MOTOR_SPEED_RERATIO * PULSE_PRE_ROUND);//算得5ms转了多少圈,除以4是因为4倍频
//			motor1.speed = Speed_Low_Filter(motor1.speed,speed_Record);//滤波函数
			motor1.lastCount = motor1.totalCount; //记录这一次的计数值
			motor1.distance = One_Circle_Distance * motor1.speed;//计算5ms移动距离（单位mm）
			sd=motor1.distance*200;//1秒移动的距离
			if(Hard_Trigger_flag==1)
			{
				Trigger_Interval=Trigger_Interval+motor1.distance*1000;
				if(Trigger_Interval>=Hard_Trigger_Interval)
				{
					Hard_Trigger_flag=0;
					Trigger_Interval=0;
				}
			}
			if(Position_flag==1)//原点校准
			{
				motor1.lastCount=0;
				motor1.totalCount=0;
				motor1.overflowNum=0;
				motor1.speed=0;
				motor1.direct = 0;
				motor1.distance = 0;
				Position=0;
				Position_upload=0;
				pluse=0;
			}
			else
			{
				Position = Position + motor1.distance;	//距原点距离
				Position_upload = Position*100;//位置上传数据（单位0.01mm）
				if(Position_upload*10==Target_Position&&Zero_regression_flag==1&&Absolute_position_flag==1)//到达绝对定位位置停止运动且之前进行过回零且接收到绝对位置
				{
					HAL_TIM_PWM_Stop_IT(&htim8,TIM_CHANNEL_1);//关闭PWM输出
					HAL_GPIO_WritePin(TIM8_CH1N_GPIO_Port,TIM8_CH1N_Pin,GPIO_PIN_SET);//PA7-电机使能正输入(GPIO_PIN_RESET:开始，GPIO_PIN_SET:停止）
					Sports_status_flag=0;	//运动状态
					Absolute_position_flag=0;
				}
			}
			if(Position_upload_flag==1)//实时位置上传
			{
				Real_time_location_array[2]=Position_upload&0xFF;
				Real_time_location_array[3]=(Position_upload>>8)&0xFF;
				Real_time_location_array[4]=(Position_upload>>16)&0xFF;
				Real_time_location_array[5]=(Position_upload>>24)&0xFF;
				send(2,Real_time_location_array,6);//向客户端发送
			}
		}
  }
}

void Pulse_Emission(void *argument)//脉冲触发（TIM13通道）
{
  for(;;)
  {
//		osDelay(1);
		if(Hard_Trigger_start_flag==1&&Position_upload>=Hard_Trigger_Position&&Sports_status_flag==1)//硬触发条件(硬触发启动，到达硬触发位置，运动状态)
		{
			if(Hard_Trigger_flag==0)
			{
				if(Hard_Trigger_Current_Number<Hard_Trigger_Number)//硬触发次数判定
				{
					Hard_Trigger_Current_Number++;
					HAL_GPIO_WritePin(IO_OUT_GPIO_Port, IO_OUT_Pin, GPIO_PIN_SET);//PA2-硬触发
					HAL_TIM_Base_Start_IT(&htim13);//开启TIM13定时器中断（10MHZ，计数500次，50us）
				}
				else
				{
					Hard_Trigger_Current_Number=0;
					Hard_Trigger_start_flag=0;
				}
			}
		}
		else if(Hard_Trigger_start_flag==0)
		{
			Hard_Trigger_Current_Number=0;
		}
  }
}

void Extreme_position_Drive(void *argument)//极限位置控制
{
	uint8_t number_a=0xff;
	uint8_t AUTORELOAD=0X0F;
  for(;;)
  {
		osDelay(1);
		if(Extreme_position_flag==1&&Sports_status_flag==1)
		{
			HAL_GPIO_WritePin(TIM8_CH1N_GPIO_Port,TIM8_CH1N_Pin,GPIO_PIN_RESET);//PA7-电机使能正输入(GPIO_PIN_RESET:开始，GPIO_PIN_SET:停止）
			osDelay(1);
			HAL_GPIO_TogglePin(GPIOC,GPIO_PIN_7);//控制电机驱动控制电机正反转
			osDelay(1);
			if(zero_return_speed_value==500)
			{
				AUTORELOAD=0x4C;
			}
			else if(zero_return_speed_value==1000)
			{
				AUTORELOAD=0x26;
			}
			else if(zero_return_speed_value==1500)
			{
				AUTORELOAD=0x19;
			}
			else if(zero_return_speed_value==2000)
			{
				AUTORELOAD=0x12;
			}
			else if(zero_return_speed_value>=2500)
			{
				AUTORELOAD=0x0F;
			}
			while(number_a>AUTORELOAD)
			{
				number_a--;
				HAL_TIM_Base_Start_IT(&htim8);//开启TIM8定时器中断（20KHZ，周期50us）
				__HAL_TIM_SET_AUTORELOAD(&htim8,number_a);//修改自动重装载值
				HAL_TIM_PWM_Start_IT(&htim8,TIM_CHANNEL_1);//启动TIM8_CH1的PWM波输出（中断）
				if(number_a>=0x96)
				{
					HAL_Delay(5);
				}
				else if(0x96>number_a&&number_a>=0x28)
				{
					HAL_Delay(15);
				}
				else
				{
					HAL_Delay(20);
				}
			}
			number_a=0xff;
			Extreme_position_flag=0;
		}
  }
}
/* USER CODE END Application */
